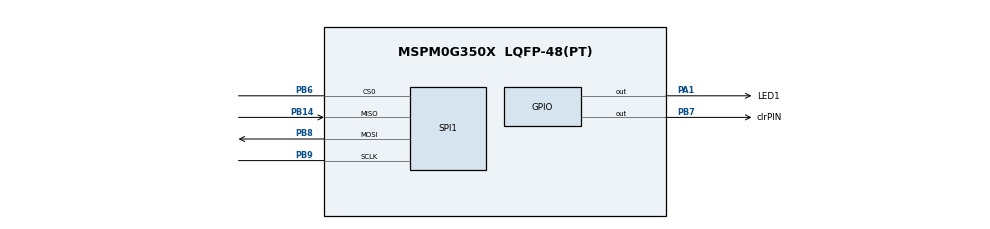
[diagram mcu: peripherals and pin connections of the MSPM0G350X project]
/**
 * @cliArgs --device "MSPM0G350X" --part "Default" --package "LQFP-48(PT)" --product "mspm0_sdk@2.10.00.04"
 * @versions {"tool":"1.26.2+4477"}
 */

/**
 * Import the modules used in this configuration.
 */
const Board  = scripting.addModule("/ti/driverlib/Board");
const GPIO   = scripting.addModule("/ti/driverlib/GPIO", {}, false);
const GPIO1  = GPIO.addInstance();
const GPIO2  = GPIO.addInstance();
const SPI    = scripting.addModule("/ti/driverlib/SPI", {}, false);
const SPI1   = SPI.addInstance();
const SYSCTL = scripting.addModule("/ti/driverlib/SYSCTL");

/**
 * Write custom configuration values to the imported modules.
 */

GPIO1.$name                          = "gpioLED";
GPIO1.associatedPins[0].initialValue = "SET";
GPIO1.associatedPins[0].$name        = "LED1";
GPIO1.associatedPins[0].pin.$assign  = "PA1";

GPIO2.$name                         = "gpioCLR";
GPIO2.associatedPins[0].$name       = "clrPIN";
GPIO2.associatedPins[0].pin.$assign = "PB7";

SPI1.$name                              = "mySPI";
SPI1.phase                              = "1";
SPI1.peripheral.sclkPin.$assign         = "PB9";
SPI1.peripheral.mosiPin.$assign         = "PB8";
SPI1.peripheral.misoPin.$assign         = "PB14";
SPI1.peripheral.cs0Pin.$assign          = "PB6";
SPI1.sclkPinConfig.$name                = "ti_driverlib_gpio_GPIOPinGeneric0";
SPI1.sclkPinConfig.direction            = scripting.forceWrite("OUTPUT");
SPI1.sclkPinConfig.onlyInternalResistor = scripting.forceWrite(false);
SPI1.sclkPinConfig.passedPeripheralType = scripting.forceWrite("Digital");
SPI1.mosiPinConfig.$name                = "ti_driverlib_gpio_GPIOPinGeneric1";
SPI1.mosiPinConfig.direction            = scripting.forceWrite("OUTPUT");
SPI1.mosiPinConfig.hideOutputInversion  = scripting.forceWrite(false);
SPI1.mosiPinConfig.onlyInternalResistor = scripting.forceWrite(false);
SPI1.mosiPinConfig.passedPeripheralType = scripting.forceWrite("Digital");
SPI1.misoPinConfig.$name                = "ti_driverlib_gpio_GPIOPinGeneric2";
SPI1.misoPinConfig.onlyInternalResistor = scripting.forceWrite(false);
SPI1.misoPinConfig.passedPeripheralType = scripting.forceWrite("Digital");
SPI1.misoPinConfig.enableConfig         = true;
SPI1.cs0PinConfig.$name                 = "ti_driverlib_gpio_GPIOPinGeneric3";
SPI1.cs0PinConfig.direction             = scripting.forceWrite("OUTPUT");
SPI1.cs0PinConfig.hideOutputInversion   = scripting.forceWrite(false);
SPI1.cs0PinConfig.onlyInternalResistor  = scripting.forceWrite(false);
SPI1.cs0PinConfig.passedPeripheralType  = scripting.forceWrite("Digital");
SPI1.cs0PinConfig.enableConfig          = true;

SYSCTL.clockTreeEn = true;

/**
 * Pinmux solution for unlocked pins/peripherals. This ensures that minor changes to the automatic solver in a future
 * version of the tool will not impact the pinmux you originally saw.  These lines can be completely deleted in order to
 * re-solve from scratch.
 */
Board.peripheral.$suggestSolution          = "DEBUGSS";
Board.peripheral.swclkPin.$suggestSolution = "PA20";
Board.peripheral.swdioPin.$suggestSolution = "PA19";
SPI1.peripheral.$suggestSolution           = "SPI1";
